# STM32H5F5 register map
File version: 1.0
CPU: CM33 r0p0, little endian, MPU, FPU, 4 interrupt priority bits
Registers are 32-bit, read-write, reset 0x0 unless marked. A register's access mark holds for its fields unless they carry their own. Offsets are from the block's base; [hi:lo] are bit positions; {n}, {i} and the like mark numbered series; 'fields as' and 'values as' point back to an identical list.

## RCC (part 2 of 2) — RCC register block
Base 0x44020C00
Same registers: RCC_S 0x54020C00
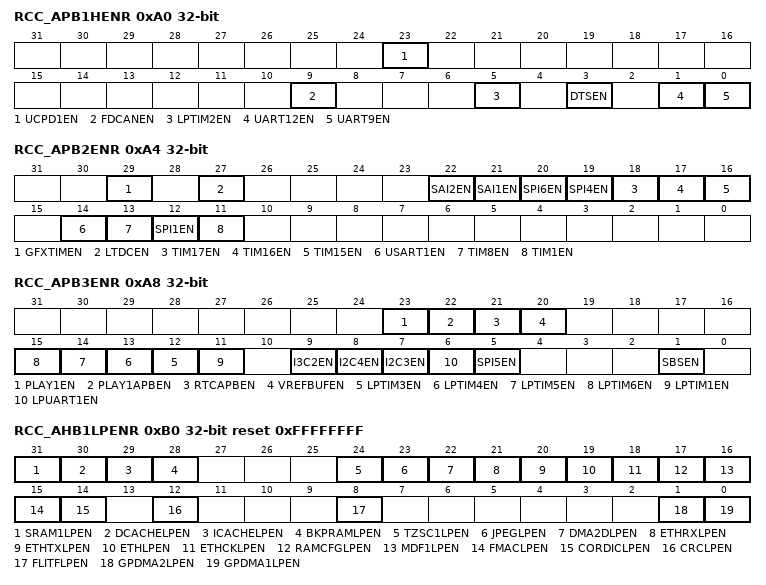
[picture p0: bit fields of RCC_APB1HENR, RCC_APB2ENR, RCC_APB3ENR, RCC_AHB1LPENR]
0xA0 RCC_APB1HENR — RCC APB1 peripheral clock register
  [23] UCPD1EN — UCPD1 clock enable
    0=UCPD1 clock disabled (default after reset); 1=UCPD1 clock enabled
  [9] FDCANEN — FDCAN1/2/3 clock enable
    0=FDCAN1/2/3 clock disabled (default after reset); 1=FDCAN1/2/3 clock enabled
  [5] LPTIM2EN — LPTIM2 clock enable
    0=LPTIM2 disabled (default after reset); 1=LPTIM2 peripheral clock enabled
  [3] DTSEN — DTS clock enable
    0=DTS clock disabled (default after reset); 1=DTS clock enabled
  [1] UART12EN — UART12 clock enable
    0=UART12 clock disabled (default after reset); 1=UART12 clock enabled
  [0] UART9EN — UART9 clock enable
    0=UART9 clock disabled (default after reset); 1=UART9 clock enabled
0xA4 RCC_APB2ENR — RCC APB2 peripheral clock register
  [29] GFXTIMEN — GFXTIM clock enable
    0=GFXTIM clock disabled (default after reset); 1=GFXTIM clock enabled
  [27] LTDCEN — LTDC clock enable
    0=LTDC clock disabled; 1=LTDC clock enabled
  [22] SAI2EN — SAI2 clock enable
    0=SAI2 clock disabled; 1=SAI2 clock enabled
  [21] SAI1EN — SAI1 clock enable
    0=SAI1 clock disabled (default after reset); 1=SAI1 clock enabled
  [20] SPI6EN — SPI6 clock enable
    0=SPI6 clock disabled (default after reset); 1=SPI6 clock enabled
  [19] SPI4EN — SPI4 clock enable
    0=SPI4 clock disabled (default after reset); 1=SPI4 clock enabled
  [18] TIM17EN — TIM17 clock enable
    0=TIM17 clock disabled (default after reset); 1=TIM17 clock enabled
  [17] TIM16EN — TIM16 clock enable
    0=TIM16 clock disabled (default after reset); 1=TIM16 clock enabled
  [16] TIM15EN — TIM15 clock enable
    0=TIM15 clock disabled (default after reset); 1=TIM15 clock enabled
  [14] USART1EN — USART1 clock enable
    0=USART1 clock disabled (default after reset); 1=USART1 clock enabled
  [13] TIM8EN — TIM8 clock enable
    0=TIM8 clock disabled (default after reset); 1=TIM8 clock enabled
  [12] SPI1EN — SPI1 clock enable
    0=SPI1 clock disabled (default after reset); 1=SPI1 clock enabled
  [11] TIM1EN — TIM1 clock enable
    0=TIM1 clock disabled (default after reset); 1=TIM1 clock enabled
0xA8 RCC_APB3ENR — RCC APB3 peripheral clock register
  [23] PLAY1EN — PLAY1 clock enable
    0=PLAY1 clock disabled (default after reset); 1=PLAY1 clock enabled
  [22] PLAY1APBEN — clock enable for PLAY1 configuration
    values as PLAY1EN
  [21] RTCAPBEN — RTC APB interface clock enable
    0=RTC APB interface clock disabled (default after reset); 1=RTC APB interface clock enabled
  [20] VREFBUFEN — VREFBUF clock enable
    0=VREFBUF clock disabled (default after reset); 1=VREFBUF clock enabled
  [n+9] LPTIM{n}EN (n=3..6) — LPTIM{n} clock enable
    0=LPTIM{n} clock disabled (default after reset); 1=LPTIM{n} clock enabled
  [11] LPTIM1EN — LPTIM1 clock enable
    0=LPTIM1 clock disabled (default after reset); 1=LPTIM1 clock enabled
  [9] I3C2EN — I3C2 clock enable
    0=I3C2 clock disabled (default after reset); 1=I3C2 clock enabled
  [8] I2C4EN — I2C4 clock enable
    0=I2C4 clock disabled (default after reset); 1=I2C4 clock enabled
  [7] I2C3EN — I2C3 clock enable
    0=I2C3 clock disabled (default after reset); 1=I2C3 clock enabled
  [6] LPUART1EN — LPUART1 clock enable
    0=LPUART1 clock disabled (default after reset); 1=LPUART1 clock enabled
  [5] SPI5EN — SPI5 clock enable
    0=SPI5 clock disabled (default after reset); 1=SPI5 clock enabled
  [1] SBSEN — SBS clock enable
    0=SBS clock disabled (default after reset); 1=SBS clock enabled
0xB0 RCC_AHB1LPENR reset 0xFFFFFFFF — RCC AHB1 sleep clock register
  [31] SRAM1LPEN — SRAM1 clock enable during Sleep mode
    0=SRAM1 clock disabled during Sleep mode; 1=SRAM1 clock enabled during Sleep mode (default after reset)
  [30] DCACHELPEN — DCACHE clock enable during Sleep mode
    0=DCACHE clock disabled during Sleep mode; 1=DCACHE clock enabled during Sleep mode (default after reset)
  [29] ICACHELPEN — ICACHE clock enable during Sleep mode
    0=ICACHE clock disabled during Sleep mode; 1=ICACHE clock enabled during Sleep mode (default after reset)
  [28] BKPRAMLPEN — BKPRAM clock enable during Sleep mode
    0=BKPRAM clock disabled during Sleep mode; 1=BKPRAM clock enabled during Sleep mode (default after reset)
  [24] TZSC1LPEN — TZSC1 clock enable during Sleep mode
    0=TZSC1 clock disabled during Sleep mode; 1=TZSC1 clock enabled during Sleep mode (default after reset)
  [23] JPEGLPEN — JPEG clock enable during Sleep mode
    0=JPEG clock disabled during Sleep mode; 1=JPEG clock enabled during Sleep mode (default after reset)
  [22] DMA2DLPEN — DMA2D clock enable during Sleep mode
    0=DMA2D clock disabled during Sleep mode; 1=DMA2D clock enabled during Sleep mode (default after reset)
  [21] ETHRXLPEN — ETHRX clock enable during Sleep mode
    0=ETHRX clock disabled during Sleep mode; 1=ETHRX clock enabled during Sleep mode (default after reset)
  [20] ETHTXLPEN — ETHTX clock enable during Sleep mode
    0=ETHTX clock disabled during Sleep mode; 1=ETHTX clock enabled during Sleep mode (default after reset)
  [19] ETHLPEN — ETH clock enable during Sleep mode
    0=ETH clock disabled during Sleep mode; 1=ETH clock enabled during Sleep mode (default after reset)
  [18] ETHCKLPEN — ETH internal clock enable during Sleep mode
    0=ETH internal clock disabled during Sleep mode; 1=ETH internal clock enabled during Sleep mode (default after reset)
  [17] RAMCFGLPEN — RAMCFG clock enable during Sleep mode
    0=RAMCFG clock disabled during Sleep mode; 1=RAMCFG clock enabled during Sleep mode (default after reset)
  [16] MDF1LPEN — MDF1 clock enable during Sleep mode
    0=MDF1 clock disabled during Sleep mode; 1=MDF1 clock enabled during Sleep mode (default after reset)
  [15] FMACLPEN — FMAC clock enable during Sleep mode
    0=FMAC clock disabled during Sleep mode; 1=FMAC clock enabled during Sleep mode (default after reset)
  [14] CORDICLPEN — CORDIC clock enable during Sleep mode
    0=CORDIC clock disabled during Sleep mode; 1=CORDIC clock enabled during Sleep mode (default after reset)
  [12] CRCLPEN — CRC clock enable during Sleep mode
    0=CRC clock disabled during Sleep mode; 1=CRC clock enabled during Sleep mode (default after reset)
  [8] FLITFLPEN — Flash interface (FLITF) clock enable during Sleep mode
    0=FLITF clock disabled during Sleep mode; 1=FLITF clock enabled during Sleep mode (default after reset)
  [1] GPDMA2LPEN — GPDMA2 clock enable during Sleep mode
    0=GPDMA2 clock disabled during Sleep mode; 1=GPDMA2 clock enabled during Sleep mode (default after reset)
  [0] GPDMA1LPEN — GPDMA1 clock enable during Sleep mode
    0=GPDMA1 clock disabled during Sleep mode; 1=GPDMA1 clock enabled during Sleep mode (default after reset)
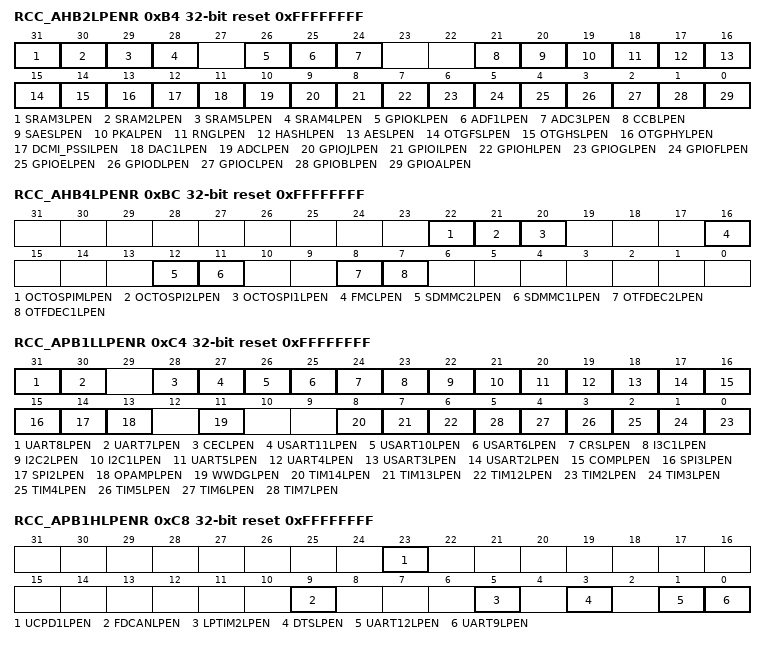
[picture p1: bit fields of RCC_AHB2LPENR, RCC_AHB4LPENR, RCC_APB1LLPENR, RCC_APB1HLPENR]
0xB4 RCC_AHB2LPENR reset 0xFFFFFFFF — RCC AHB2 sleep clock register
  [31] SRAM3LPEN — SRAM3 clock enable during Sleep mode
    0=SRAM3 clock disabled during Sleep mode; 1=SRAM3 clock enabled during Sleep mode (default after reset)
  [30] SRAM2LPEN — SRAM2 clock enable during Sleep mode
    0=SRAM2 clock disabled during Sleep mode; 1=SRAM2 clock enabled during Sleep mode (default after reset)
  [29] SRAM5LPEN — SRAM5 clock enable during Sleep mode
    0=SRAM5 clock disabled during Sleep mode; 1=SRAM5 clock enabled during Sleep mode (default after reset)
  [28] SRAM4LPEN — SRAM4 clock enable during Sleep mode
    0=SRAM4 clock disabled during Sleep mode; 1=SRAM4 clock enabled during Sleep mode (default after reset)
  [26] GPIOKLPEN — GPIOK clock enable during Sleep mode
    0=GPIOK clock disabled during Sleep mode; 1=GPIOK clock enabled during Sleep mode (default after reset)
  [25] ADF1LPEN — ADF1 clock enable during Sleep mode
    0=ADF1 clock disabled during Sleep mode; 1=ADF1 clock enabled during Sleep mode (default after reset)
  [24] ADC3LPEN — ADC3 clock enable during Sleep mode
    0=ADC3 clock disabled during Sleep mode; 1=ADC3 clock enabled during Sleep mode (default after reset)
  [21] CCBLPEN — CCB clock enable during Sleep mode
    0=CCB clock disabled during Sleep mode; 1=CCB clock enabled during Sleep mode (default after reset)
  [20] SAESLPEN — SAES clock enable during Sleep mode
    0=SAES clock disabled during Sleep mode; 1=SAES clock enabled during Sleep mode (default after reset)
  [19] PKALPEN — PKA clock enable during Sleep mode
    0=PKA clock disabled during Sleep mode; 1=PKA clock enabled during Sleep mode (default after reset)
  [18] RNGLPEN — RNG clock enable during Sleep mode
    0=RNG clock disabled during Sleep mode; 1=RNG clock enabled during Sleep mode (default after reset)
  [17] HASHLPEN — HASH clock enable during Sleep mode
    0=HASH clock disabled during Sleep mode; 1=HASH clock enabled during Sleep mode (default after reset)
  [16] AESLPEN — AES clock enable during Sleep mode
    0=AES clock disabled during Sleep mode; 1=AES clock enabled during Sleep mode (default after reset)
  [15] OTGFSLPEN — OTGFS clock enable during Sleep mode
    0=OTGFS clock disabled during Sleep mode; 1=OTGFS clock enabled during Sleep mode (default after reset)
  [14] OTGHSLPEN — OTGHS clock enable during Sleep mode
    0=OTGHS clock disabled during Sleep mode; 1=OTGHS clock enabled during Sleep mode (default after reset)
  [13] OTGPHYLPEN — OTGPHY clock enable during Sleep mode
    0=OTGPHY clock disabled during Sleep mode; 1=OTGPHY clock enabled during Sleep mode (default after reset)
  [12] DCMI_PSSILPEN — Digital camera interface clock enable during Sleep mode (DCMI or PSSI, depending which interface is active)
    0=DCMI/PSSI clock disabled during Sleep mode; 1=DCMI/PSSI clock enabled during Sleep mode (default after reset)
  [11] DAC1LPEN — DAC clock enable during Sleep mode
    0=DAC clock disabled during Sleep mode; 1=DAC clock enabled during Sleep mode (default after reset)
  [10] ADCLPEN — ADC1/2 clock enable during Sleep mode
    0=ADC1/2 clock disabled during Sleep mode; 1=ADC1/2 clock enabled during Sleep mode (default after reset)
  [9] GPIOJLPEN — GPIOJ clock enable during Sleep mode
    0=GPIOJ clock disabled during Sleep mode; 1=GPIOJ clock enabled during Sleep mode (default after reset)
  [8] GPIOILPEN — GPIOI clock enable during Sleep mode
    0=GPIOI clock disabled during Sleep mode; 1=GPIOI clock enabled during Sleep mode (default after reset)
  [7] GPIOHLPEN — GPIOH clock enable during Sleep mode
    0=GPIOH clock disabled during Sleep mode; 1=GPIOH clock enabled during Sleep mode (default after reset)
  [6] GPIOGLPEN — GPIOG clock enable during Sleep mode
    0=GPIOG clock disabled during Sleep mode; 1=GPIOG clock enabled during Sleep mode (default after reset)
  [5] GPIOFLPEN — GPIOF clock enable during Sleep mode
    0=GPIOF clock disabled during Sleep mode; 1=GPIOF clock enabled during Sleep mode (default after reset)
  [4] GPIOELPEN — GPIOE clock enable during Sleep mode
    0=GPIOE clock disabled during Sleep mode; 1=GPIOE clock enabled during Sleep mode (default after reset)
  [3] GPIODLPEN — GPIOD clock enable during Sleep mode
    0=GPIOD clock disabled during Sleep mode; 1=GPIOD clock enabled during Sleep mode (default after reset)
  [2] GPIOCLPEN — GPIOC clock enable during Sleep mode
    0=GPIOC clock disabled during Sleep mode; 1=GPIOC clock enabled during Sleep mode (default after reset)
  [1] GPIOBLPEN — GPIOB clock enable during Sleep mode
    0=GPIOB clock disabled during Sleep mode; 1=GPIOB clock enabled during Sleep mode (default after reset)
  [0] GPIOALPEN — GPIOA clock enable during Sleep mode
    0=GPIOA clock disabled during Sleep mode; 1=GPIOA clock enabled during Sleep mode (default after reset)
0xBC RCC_AHB4LPENR reset 0xFFFFFFFF — RCC AHB4 sleep clock register
  [22] OCTOSPIMLPEN — OCTOSPIM clock enable during Sleep mode
    0=OCTOSPIM clock disabled during Sleep mode; 1=OCTOSPIM clock enabled during Sleep mode (default after reset)
  [21] OCTOSPI2LPEN — OCTOSPI2 clock enable during Sleep mode
    0=OCTOSPI2 clock disabled during Sleep mode; 1=OCTOSPI2 clock enabled during Sleep mode (default after reset)
  [20] OCTOSPI1LPEN — OCTOSPI1 clock enable during Sleep mode
    0=OCTOSPI1 clock disabled during Sleep mode; 1=OCTOSPI1 clock enabled during Sleep mode (default after reset)
  [16] FMCLPEN — FMC clock enable during Sleep mode
    0=FMC clock disabled during Sleep mode; 1=FMC clock enabled during Sleep mode (default after reset)
  [12] SDMMC2LPEN — SDMMC2 and SDMMC2 delay clock enable during Sleep mode
    0=SDMMC2 and SDMMC2 delay clock disabled during Sleep mode; 1=SDMMC2 and SDMMC2 delay clock enabled during Sleep mode (default after reset)
  [11] SDMMC1LPEN — SDMMC1 and SDMMC1 delay clock enable during Sleep mode
    0=SDMMC1 and SDMMC1 delay clock disabled during Sleep mode; 1=SDMMC1 and SDMMC1 delay clock enabled during Sleep mode (default after reset)
  [8] OTFDEC2LPEN — OTFDEC2 clock enable during Sleep mode
    0=OTFDEC2 clock disabled during Sleep mode; 1=OTFDEC2 clock enabled during Sleep mode (default after reset)
  [7] OTFDEC1LPEN — OTFDEC1 clock enable during Sleep mode
    0=OTFDEC1 clock disabled during Sleep mode; 1=OTFDEC1 clock enabled during Sleep mode (default after reset)
0xC4 RCC_APB1LLPENR reset 0xFFFFFFFF — RCC APB1 sleep clock register
  [31] UART8LPEN — UART8 clock enable during Sleep mode
    0=UART8 clock disabled during Sleep mode; 1=UART8 clock enabled during Sleep mode (default after reset)
  [30] UART7LPEN — UART7 clock enable during Sleep mode
    0=UART7 clock disabled during Sleep mode; 1=UART7 clock enabled during Sleep mode (default after reset)
  [28] CECLPEN — HDMI-CEC clock enable during Sleep mode
    0=HDMI-CEC clock disabled during Sleep mode; 1=HDMI-CEC clock enabled during Sleep mode (default after reset)
  [27] USART11LPEN — USART11 clock enable during Sleep mode
    0=USART11 clock disabled during Sleep mode; 1=USART11 clock enabled during Sleep mode (default after reset)
  [26] USART10LPEN — USART10 clock enable during Sleep mode
    0=USART10 clock disabled during Sleep mode; 1=USART10 clock enabled during Sleep mode (default after reset)
  [25] USART6LPEN — USART6 clock enable during Sleep mode
    0=USART6 clock disabled during Sleep mode; 1=USART6 clock enabled during Sleep mode (default after reset)
  [24] CRSLPEN — CRS clock enable during Sleep mode
    0=CRS clock disabled during Sleep mode; 1=CRS clock enabled during Sleep mode (default after reset)
  [23] I3C1LPEN — I3C1 clock enable during Sleep mode
    0=I3C1 clock disabled during Sleep mode; 1=I3C1 clock enabled during Sleep mode (default after reset)
  [22] I2C2LPEN — I2C2 clock enable during Sleep mode
    0=I2C2 clock disabled during Sleep mode; 1=I2C2 clock enabled during Sleep mode (default after reset)
  [21] I2C1LPEN — I2C1 clock enable during Sleep mode
    0=I2C1 clock disabled during Sleep mode; 1=I2C1 clock enabled during Sleep mode (default after reset)
  [20] UART5LPEN — UART5 clock enable during Sleep mode
    0=UART5 clock disabled during Sleep mode; 1=UART5 clock enabled during Sleep mode (default after reset)
  [19] UART4LPEN — UART4 clock enable during Sleep mode
    0=UART4 clock disabled during Sleep mode; 1=UART4 clock enabled during Sleep mode (default after reset)
  [18] USART3LPEN — USART3 clock enable during Sleep mode
    0=USART3 clock disabled during Sleep mode; 1=USART3 clock enabled during Sleep mode (default after reset)
  [17] USART2LPEN — USART2 clock enable during Sleep mode
    0=USART2 clock disabled during Sleep mode; 1=USART2 clock enabled during Sleep mode (default after reset)
  [16] COMPLPEN — COMP clock enable during Sleep mode
    0=COMP clock disabled during Sleep mode; 1=COMP clock enabled during Sleep mode (default after reset)
  [15] SPI3LPEN — SPI3 clock enable during Sleep mode
    0=SPI3 clock disabled during Sleep mode; 1=SPI3 clock enabled during Sleep mode (default after reset)
  [14] SPI2LPEN — SPI2 clock enable during Sleep mode
    0=SPI2 clock disabled during Sleep mode; 1=SPI2 clock enabled during Sleep mode (default after reset)
  [13] OPAMPLPEN — OPAMP clock enable during Sleep mode
    0=OPAMP clock disabled during Sleep mode; 1=OPAMP clock enabled during Sleep mode (default after reset)
  [11] WWDGLPEN — WWDG clock enable during Sleep mode
    0=WWDG clock disabled during Sleep mode; 1=WWDG clock enabled during Sleep mode (default after reset)
  [8] TIM14LPEN — TIM14 clock enable during Sleep mode
    0=TIM14 clock disabled during Sleep mode; 1=TIM14 clock enabled during Sleep mode (default after reset)
  [7] TIM13LPEN — TIM13 clock enable during Sleep mode
    0=TIM13 clock disabled during Sleep mode; 1=TIM13 clock enabled during Sleep mode (default after reset)
  [6] TIM12LPEN — TIM12 clock enable during Sleep mode
    0=TIM12 clock disabled during Sleep mode; 1=TIM12 clock enabled during Sleep mode (default after reset)
  [n-2] TIM{n}LPEN (n=2..7) — TIM{n} clock enable during Sleep mode
    0=TIM{n} clock disabled during Sleep mode; 1=TIM{n} clock enabled during Sleep mode (default after reset)
0xC8 RCC_APB1HLPENR reset 0xFFFFFFFF — RCC APB1 sleep clock register
  [23] UCPD1LPEN — UCPD1 clock enable during Sleep mode
    0=UCPD1 clock disabled during Sleep mode; 1=UCPD1 clock enabled during Sleep mode (default after reset)
  [9] FDCANLPEN — FDCAN1/2/3 clock enable during Sleep mode
    0=FDCAN1/2/3 clock disabled during Sleep mode; 1=FDCAN1/2/3 clock enabled during Sleep mode (default after reset)
  [5] LPTIM2LPEN — LPTIM2 clock enable during Sleep mode
    0=LPTIM2 clock disabled during Sleep mode; 1=LPTIM2 clock enabled during Sleep mode (default after reset)
  [3] DTSLPEN — DTS clock enable during Sleep mode
    0=DTS clock disabled during Sleep mode; 1=DTS clock enabled during Sleep mode (default after reset)
  [1] UART12LPEN — UART12 clock enable during Sleep mode
    0=UART12 clock disabled during Sleep mode; 1=UART12 clock enabled during Sleep mode (default after reset)
  [0] UART9LPEN — UART9 clock enable during Sleep mode
    0=UART9 clock disabled during Sleep mode; 1=UART9 clock enabled during Sleep mode (default after reset)
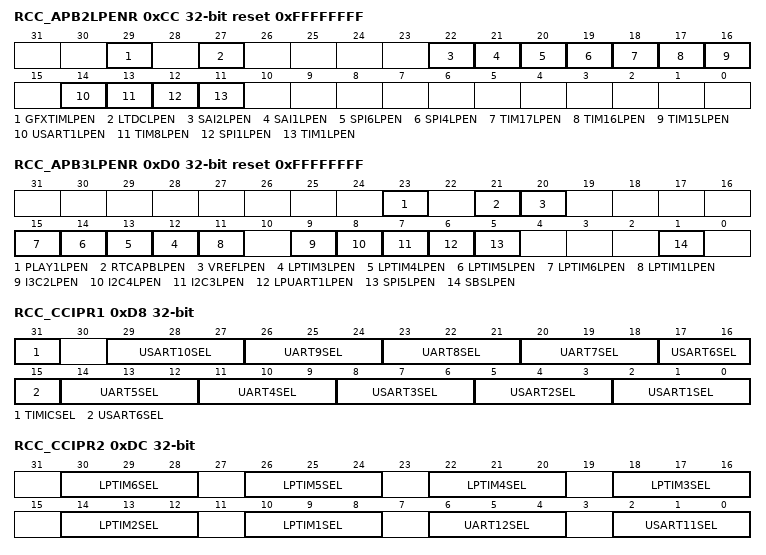
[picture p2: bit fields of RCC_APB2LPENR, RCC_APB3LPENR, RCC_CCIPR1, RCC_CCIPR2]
0xCC RCC_APB2LPENR reset 0xFFFFFFFF — RCC APB2 sleep clock register
  [29] GFXTIMLPEN — GFXTIM clock enable during Sleep mode
    0=GFXTIM clock disabled during Sleep mode; 1=GFXTIM clock enabled during Sleep mode (default after reset)
  [27] LTDCLPEN — LTDC clock enable during Sleep mode
    0=LTDC clock disabled during Sleep mode; 1=LTDC clock enabled during Sleep mode (default after reset)
  [22] SAI2LPEN — SAI2 clock enable during Sleep mode
    0=SAI2 clock disabled during Sleep mode; 1=SAI2 clock enabled during Sleep mode (default after reset)
  [21] SAI1LPEN — SAI1 clock enable during Sleep mode
    0=SAI1 clock disabled during Sleep mode; 1=SAI1 clock enabled during Sleep mode (default after reset)
  [20] SPI6LPEN — SPI6 clock enable during Sleep mode
    0=SPI6 clock disabled during Sleep mode; 1=SPI6 clock enabled during Sleep mode (default after reset)
  [19] SPI4LPEN — SPI4 clock enable during Sleep mode
    0=SPI4 clock disabled during Sleep mode; 1=SPI4 clock enabled during Sleep mode (default after reset)
  [18] TIM17LPEN — TIM17 clock enable during Sleep mode
    0=TIM17 clock disabled during Sleep mode; 1=TIM17 clock enabled during Sleep mode (default after reset)
  [17] TIM16LPEN — TIM16 clock enable during Sleep mode
    0=TIM16 clock disabled during Sleep mode; 1=TIM16 clock enabled during Sleep mode (default after reset)
  [16] TIM15LPEN — TIM15 clock enable during Sleep mode
    0=TIM15 clock disabled during Sleep mode; 1=TIM15 clock enabled during Sleep mode (default after reset)
  [14] USART1LPEN — USART1 clock enable during Sleep mode
    0=USART1 clock disabled during Sleep mode; 1=USART1 clock enabled during Sleep mode (default after reset)
  [13] TIM8LPEN — TIM8 clock enable during Sleep mode
    0=TIM8 clock disabled during Sleep mode; 1=TIM8 clock enabled during Sleep mode (default after reset)
  [12] SPI1LPEN — SPI1 clock enable during Sleep mode
    0=SPI1 clock disabled during Sleep mode; 1=SPI1 clock enabled during Sleep mode (default after reset)
  [11] TIM1LPEN — TIM1 clock enable during Sleep mode
    0=TIM1 clock disabled during Sleep mode; 1=TIM1 clock enabled during Sleep mode (default after reset)
0xD0 RCC_APB3LPENR reset 0xFFFFFFFF — RCC APB3 sleep clock register
  [23] PLAY1LPEN — PLAY1 clock enable during Sleep mode
    0=PLAY1 clock disabled during Sleep mode; 1=PLAY1 clock enabled during Sleep mode (default after reset)
  [21] RTCAPBLPEN — RTC APB interface clock enable during Sleep mode
    0=RTC APB interface clock disabled during Sleep mode; 1=RTC APB interface clock enabled during Sleep mode (default after reset)
  [20] VREFLPEN — VREFBUF clock enable during Sleep mode
    0=VREFBUF clock disabled during Sleep mode; 1=VREFBUF clock enabled during Sleep mode (default after reset)
  [n+9] LPTIM{n}LPEN (n=3..6) — LPTIM{n} clock enable during Sleep mode
    0=LPTIM{n} clock disabled during Sleep mode; 1=LPTIM{n} clock enabled during Sleep mode (default after reset)
  [11] LPTIM1LPEN — LPTIM1 clock enable during Sleep mode
    0=LPTIM1 clock disabled during Sleep mode; 1=LPTIM1 clock enabled during Sleep mode (default after reset)
  [9] I3C2LPEN — I3C2 clock enable during Sleep mode
    0=I3C2 clock disabled during Sleep mode; 1=I3C2 clock enabled during Sleep mode (default after reset)
  [8] I2C4LPEN — I2C4 clock enable during Sleep mode
    0=I2C4 clock disabled during Sleep mode; 1=I2C4 clock enabled during Sleep mode (default after reset)
  [7] I2C3LPEN — I2C3 clock enable during Sleep mode
    0=I2C3 clock disabled during Sleep mode; 1=I2C3 clock enabled during Sleep mode (default after reset)
  [6] LPUART1LPEN — LPUART1 clock enable during Sleep mode
    0=LPUART1 clock disabled during Sleep mode; 1=LPUART1 clock enabled during Sleep mode (default after reset)
  [5] SPI5LPEN — SPI5 clock enable during Sleep mode
    0=SPI5 clock disabled during Sleep mode; 1=SPI5 clock enabled during Sleep mode (default after reset)
  [1] SBSLPEN — SBS clock enable during Sleep mode
    0=SBS clock disabled during Sleep mode; 1=SBS clock enabled during Sleep mode (default after reset)
0xD8 RCC_CCIPR1 — RCC kernel clock configuration register
  [31] TIMICSEL — TIM12, TIM15, and LPTIM2 input capture source selection
    0=No internal clock available for timers input capture (default after reset); 1=hsi_ker_ck/1024, hsi_ker_ck/8, and csi_ker_ck/128 selected for timers input capture
  [29:27] USART10SEL — USART10 kernel clock source selection
    0=rcc_pclk1 selected as kernel clock (default after reset); 1=pll2_q_ck selected as kernel clock; 2=pll3_q_ck selected as kernel clock; 3=hsi_ker_ck selected as kernel clock; 4=csi_ker_ck selected as kernel clock; 5=lse_ck selected as kernel clock
  [26:24] UART9SEL — UART9 kernel clock source selection
    values as USART10SEL
  [23:21] UART8SEL — UART8 kernel clock source selection
    values as USART10SEL
  [20:18] UART7SEL — UART7 kernel clock source selection
    values as USART10SEL
  [17:15] USART6SEL — USART6 kernel clock source selection
    values as USART10SEL
  [14:12] UART5SEL — UART5 kernel clock source selection
    values as USART10SEL
  [11:9] UART4SEL — UART4 kernel clock source selection
    values as USART10SEL
  [8:6] USART3SEL — USART3 kernel clock source selection
    values as USART10SEL
  [5:3] USART2SEL — USART2 kernel clock source selection
    values as USART10SEL
  [2:0] USART1SEL — USART1 kernel clock source selection
    0=rcc_pclk2 selected as kernel clock (default after reset); 1=pll2_q_ck selected as kernel clock; 2=pll3_q_ck selected as kernel clock; 3=hsi_ker_ck selected as kernel clock; 4=csi_ker_ck selected as kernel clock; 5=lse_ck selected as kernel clock
0xDC RCC_CCIPR2 — RCC kernel clock configuration register
  [4n+6:4n+4] LPTIM{n}SEL (n=3..6) — LPTIM{n} kernel clock source selection
    0=rcc_pclk3 selected as kernel clock (default after reset); 1=pll2_p_ck selected as kernel clock; 2=pll3_r_ck selected as kernel clock; 3=lse_ker_ck selected as kernel clock; 4=lsi_ker_ck selected as kernel clock; 5=per_ck selected as kernel clock
  [14:12] LPTIM2SEL — LPTIM2 kernel clock source selection
    0=rcc_pclk1 selected as kernel clock (default after reset); 1=pll2_p_ck selected as kernel clock; 2=pll3_r_ck selected as kernel clock; 3=lse_ker_ck selected as kernel clock; 4=lsi_ker_ck selected as kernel clock; 5=per_ck selected as kernel clock
  [10:8] LPTIM1SEL — LPTIM1 kernel clock source selection
    values as LPTIM3SEL
  [6:4] UART12SEL — UART12 kernel clock source selection
    values as RCC_CCIPR1.USART10SEL
  [2:0] USART11SEL — USART11 kernel clock source selection
    values as RCC_CCIPR1.USART10SEL
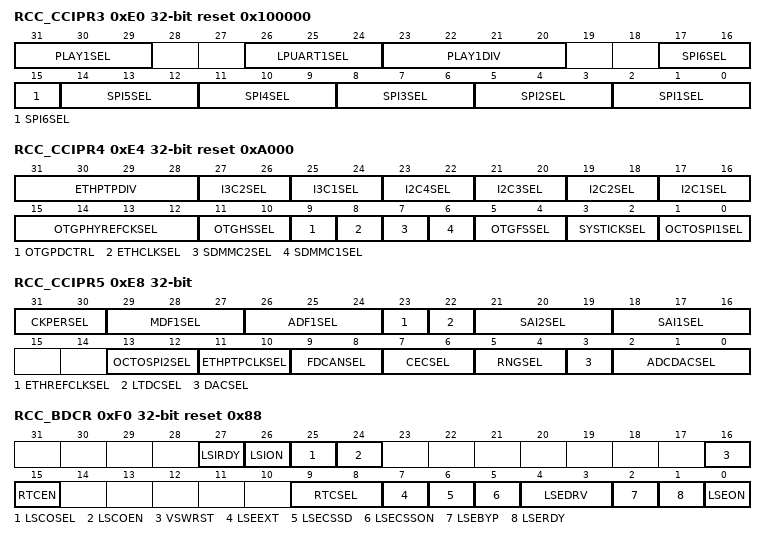
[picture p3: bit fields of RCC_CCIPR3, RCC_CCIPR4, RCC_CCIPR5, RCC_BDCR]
0xE0 RCC_CCIPR3 reset 0x100000 — RCC kernel clock configuration register
  [31:29] PLAY1SEL — PLAY1 kernel clock source selection
    0=rcc_pclk3 selected as kernel clock; 1=pll2_p_ck selected as kernel clock; 2=pll3_r_ck selected as kernel clock; 3=lse_ker_ck selected as kernel clock; 4=lsi_ker_ck selected as kernel clock; 5=per_ck selected as kernel clock
  [26:24] LPUART1SEL — LPUART1 kernel clock source selection
    0=rcc_pclk3 s elected as kernel clock (default after reset); 1=pll2_q_ck selected as kernel clock; 2=pll3_q_ck selected as kernel clock; 3=hsi_ker_ck selected as kernel clock; 4=csi_ker_ck selected as kernel clock; 5=lse_ck selected as kernel clock
  [23:20] PLAY1DIV — 2^N divider with N=0 to N=15
    0=N=0, PLAY1DIV_1; 1=N=1, PLAY1DIV_2; 2=N=2, PLAY1DIV_4; 3=N=3, PLAY1DIV_8; 15=N=15, PLAY1DIV_32768
  [17:15] SPI6SEL — SPI6 kernel clock source selection
    0=rcc_pclk2 selected as kernel clock (default after reset); 1=pll2_q_ck selected as kernel clock; 2=pll3_q_ck selected as kernel clock; 3=hsi_ker_ck selected as kernel clock; 4=csi_ker_ck selected as kernel clock; 5=hse_ck selected as kernel clock
  [14:12] SPI5SEL — SPI5 kernel clock source selection
    0=rcc_pclk3 selected as kernel clock (default after reset); 1=pll2_q_ck selected as kernel clock; 2=pll3_q_ck selected as kernel clock; 3=hsi_ker_ck selected as kernel clock; 4=csi_ker_ck selected as kernel clock; 5=hse_ck selected as kernel clock
  [11:9] SPI4SEL — SPI4 kernel clock source selection
    values as SPI6SEL
  [8:6] SPI3SEL — SPI3 kernel clock source selection
    0=pll1_q_ck selected as kernel clock (default after reset); 1=pll2_p_ck selected as kernel clock; 2=pll3_p_ck selected as kernel clock; 3=AUDIOCLK selected as kernel clock; 4=per_ck selected as kernel clock
  [5:3] SPI2SEL — SPI2 kernel clock source selection
    values as SPI3SEL
  [2:0] SPI1SEL — SPI1 kernel clock source selection
    values as SPI3SEL
0xE4 RCC_CCIPR4 reset 0xA000 — RCC kernel clock configuration register
  [31:28] ETHPTPDIV — Ethernet PTP clock division
    0=divided by 1 (default after reset); 1=divided by 2; 14=divided by 15; 15=divided by 16
  [27:26] I3C2SEL — I3C2 kernel clock source selection
    0=rcc_pclk3 selected as kernel clock (default after reset); 1=pll3_r_ck selected as kernel clock; 2=hsi_ker_ck selected as kernel clock; 3=csi_ker_ck selected as kernel clock
  [25:24] I3C1SEL — I3C1 kernel clock source selection
    0=rcc_pclk1 selected as kernel clock (default after reset); 1=pll3_r_ck selected as kernel clock; 2=hsi_ker_ck selected as kernel clock; 3=csi_ker_ck selected as kernel clock
  [23:22] I2C4SEL — I2C4 kernel clock source selection
    values as I3C2SEL
  [21:20] I2C3SEL — I2C3 kernel clock source selection
    values as I3C2SEL
  [19:18] I2C2SEL — I2C2 kernel clock source selection
    values as I3C1SEL
  [17:16] I2C1SEL — I2C1 kernel clock source selection
    values as I3C1SEL
  [15:12] OTGPHYREFCKSEL — OTG_HS PHY kernel clock frequency selection
    3=The kernel clock frequency is 16 MHz; 8=The kernel clock frequency is 19; 9=The kernel clock frequency is 20 MHz; 10=The kernel clock frequency is 24 MHz (default after reset); 14=The kernel clock frequency is 26 MHz; 11=The kernel clock frequency is 32 MHz
  [11:10] OTGHSSEL — OTG_HS PHY kernel clock source selection
    0=hse_ck selected as kernel clock (default after reset); 1=pll3_q_ck selected as kernel clock; 2=hse_ck / 2 selected as kernel clock; 3=pll1_q_ck / 2 selected as kernel clock
  [9] OTGPDCTRL — OTG_HS PHY common block power-down control
    0=In SUSPEND, PHY state machine, bias, and OTG_HS PHY PLL remain powered (default after reset); 1=In SUSPEND, PHY state machine, bias, and OTG_HS PHY PLL are powered down
  [8] ETHCLKSEL — ETH clock selection
    0=hse_ck (default after reset); 1=pll1_q_ck
  [7] SDMMC2SEL — SDMMC2 kernel clock source selection
    0=pll1_q_ck selected as kernel clock (default after reset); 1=pll2_r_ck selected as kernel clock
  [6] SDMMC1SEL — SDMMC1 kernel clock source selection
    values as SDMMC2SEL
  [5:4] OTGFSSEL — OTG_FS kernel clock source selection
    0=hsi48_ck selected as kernel clock (default after reset); 1=pll1_q_ck is selected as kernel clock; 2=pll3_q_ck selected as kernel clock; 3=clk48mohci selected as kernel clock
  [3:2] SYSTICKSEL — SYSTICK clock source selection
    0=rcc_hclk/8 selected as clock source (default after reset); 1=lsi_ker_ck selected as clock source; 2=lse_ck selected as clock source; 3=reserved, the kernel clock is disabled
  [1:0] OCTOSPI1SEL — OCTOSPI1 kernel clock source selection
    0=rcc_hclk4 selected as kernel clock (default after reset); 1=pll1_q_ck selected as kernel clock; 2=pll2_r_ck selected as kernel clock; 3=per_ck selected as kernel clock
0xE8 RCC_CCIPR5 — RCC kernel clock configuration register
  [31:30] CKPERSEL — per_ck clock source selection
    0=hsi_ker_ck selected as kernel clock (default after reset); 1=csi_ker_ck selected as kernel clock; 2=hse_ck selected as kernel clock; 3=reserved, the per_ck clock is disabled
  [29:27] MDF1SEL — MDF1 kernel clock source selection
    values as RCC_CCIPR3.SPI3SEL
  [26:24] ADF1SEL — ADF1 kernel clock source selection
    values as RCC_CCIPR3.SPI3SEL
  [23] ETHREFCLKSEL — ETH RMII reference kernel clock source selection
    0=ETH_RMII_REF_CLK (default after reset); 1=eth_clk_fb
  [22] LTDCSEL — LTDC kernel source selection
    0=pll3_r_ck selected as kernel clock (default after reset); 1=pll2_r_ck selected as kernel clock
  [21:19] SAI2SEL — SAI2 kernel clock source selection
    values as RCC_CCIPR3.SPI3SEL
  [18:16] SAI1SEL — SAI1 kernel clock source selection
    values as RCC_CCIPR3.SPI3SEL
  [13:12] OCTOSPI2SEL — OCTOSPI2 kernel clock source selection
    values as RCC_CCIPR4.OCTOSPI1SEL
  [11:10] ETHPTPCLKSEL — ETH PTP kernel clock source selection
    0=rcc_hclk1 selected as kernel clock (default after reset); 1=pll1_r_ck selected as kernel clock; 2=pll1_q_ck selected as kernel clock; 3=pll3_p_ckselected as kernel clock
  [9:8] FDCANSEL — FDCAN1, FDCAN2, and FDCAN3 kernel clock source selection
    0=hse_ck selected as kernel clock (default after reset); 1=pll1_q_ck selected as kernel clock; 2=pll2_q_ck selected as kernel clock; 3=reserved, the kernel clock is disabled
  [7:6] CECSEL — HDMI_CEC kernel clock source selection
    0=lse_ck selected as kernel clock (default after reset); 1=lsi_ker_ck selected as kernel clock; 2=csi_ker_ck/122 selected as kernel clock; 3=reserved, the kernel clock is disabled
  [5:4] RNGSEL — RNG kernel clock source selection
    0=hsi48_ck selected as kernel clock (default after reset); 1=pll1_q_ck selected as kernel clock; 2=lse_ck selected as kernel clock; 3=lsi_ker_ck selected as kernel clock
  [3] DACSEL — DAC sample and hold clock
    0=dac_hold_ck selected as kernel clock (default after reset); 1=dac_hold_ck selected as kernel clock
  [2:0] ADCDACSEL — ADC and DAC kernel clock source selection
    0=rcc_hclk selected as kernel clock (default after reset); 1=sys_ck selected as kernel clock; 2=pll2_r_ck selected as kernel clock; 3=hse_ck selected as kernel clock; 4=hsi_ker_ck selected as kernel clock; 5=csi_ker_ck selected as kernel clock
0xF0 RCC_BDCR reset 0x88 — RCC backup domain control register
  [27] LSIRDY ro — LSI oscillator ready
    0=LSI oscillator not ready; 1=LSI oscillator ready
  [26] LSION — LSI oscillator enable
    0=LSI oscillator off; 1=LSI oscillator on
  [25] LSCOSEL — Low-speed clock output selection
    0=LSI clock selected; 1=LSE clock selected
  [24] LSCOEN — Low-speed clock output (LSCO) enable
    0=LSCO output disabled; 1=LSCO output enabled
  [16] VSWRST — VSwitch domain software reset
    0=reset not activated (default after backup domain reset); 1=resets the entire VSW domain
  [15] RTCEN — RTC clock enable
    0=rtc_ck disabled (default after backup domain reset); 1=rtc_ck enabled
  [9:8] RTCSEL — RTC clock source selection
    0=no clock (default after backup domain reset); 1=LSE selected as RTC clock; 2=LSI selected as RTC clock; 3=HSE divided by RTCPRE value selected as RTC clock
  [7] LSEEXT — Low-speed external clock type in bypass mode
    1=LSE in digital mode (default after backup domain reset) (do not use if RTC is active)
  [6] LSECSSD ro — LSE clock security system failure detection
    0=no failure detected on 32 kHz oscillator (default after backup domain reset); 1=failure detected on 32 kHz oscillator
  [5] LSECSSON — LSE clock security system enable
    0=CSS on 32 kHz oscillator OFF (default after backup domain reset); 1=CSS on 32 kHz oscillator ON
  [4:3] LSEDRV — LSE oscillator driving capability
    1=medium-low drive; 2=medium-high drive; 3=highest drive
  [2] LSEBYP — LSE oscillator bypass
    0=LSE oscillator not bypassed (default after backup domain reset); 1=LSE oscillator bypassed
  [1] LSERDY — LSE oscillator ready
    0=LSE oscillator not ready (default after backup domain reset); 1=LSE oscillator ready
  [0] LSEON ro — LSE oscillator enabled
    0=LSE oscillator OFF (default after backup domain reset); 1=LSE oscillator ON
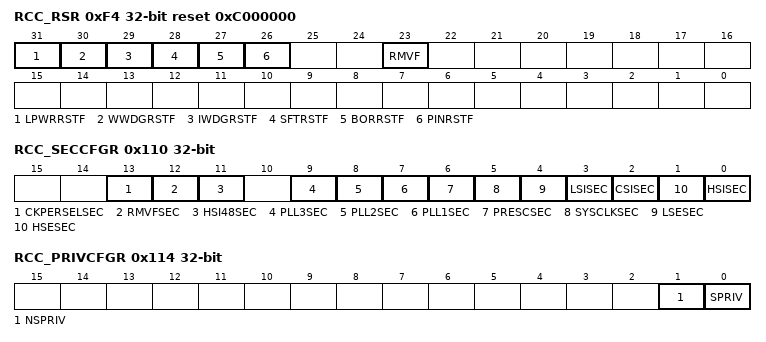
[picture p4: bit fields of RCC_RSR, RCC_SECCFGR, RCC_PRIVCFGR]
0xF4 RCC_RSR reset 0xC000000 — RCC reset status register
  [31] LPWRRSTF — Low-power reset flag
    0=no illegal low-power mode reset occurred; 1=illegal low-power mode reset occurred
  [30] WWDGRSTF — Window watchdog reset flag
    0=no window watchdog reset occurred from WWDG (default after power-on reset); 1=window watchdog reset occurred from WWDG
  [29] IWDGRSTF — Independent watchdog reset flag
    0=no independent watchdog reset occurred (default after power-on reset); 1=independent watchdog reset occurred
  [28] SFTRSTF — System reset from CPU reset flag
    0=no CPU software reset occurred (default after power-on reset); 1=a system reset has been generated by the CPU
  [27] BORRSTF — BOR reset flag
    0=no BOR reset occurred; 1=BOR reset occurred (default after power-on reset)
  [26] PINRSTF — Pin reset flag (NRST)
    0=no reset from pin occurred; 1=reset from pin occurred (default after power-on reset)
  [23] RMVF — Remove reset flag
    0=reset of the reset flags not activated (default after power-on reset); 1=resets the value of the reset flags
0x110 RCC_SECCFGR — RCC secure configuration register
  [all] fields
    0=non-secure; 1=secure
  [13] CKPERSELSEC — per_ck selection security
  [12] RMVFSEC — Remove reset flag security
  [11] HSI48SEC — HSI48 clock configuration and status bits security
  [9] PLL3SEC — PLL3 clock configuration and status bits security
  [8] PLL2SEC — PLL2 clock configuration and status bits security
  [7] PLL1SEC — PLL1 clock configuration and status bits security
  [6] PRESCSEC — AHBx/APBx prescaler configuration bits security
  [5] SYSCLKSEC — SYSCLK clock selection, STOPWUCK bit, clock output on MCO configuration security
  [4] LSESEC — LSE clock configuration and status bits security
  [3] LSISEC — LSI clock configuration and status bits security
  [2] CSISEC — CSI clock configuration and status bits security
  [1] HSESEC — HSE clock configuration bits, status bits and HSE_CSS security
  [0] HSISEC — HSI clock configuration and status bits security
0x114 RCC_PRIVCFGR — RCC privilege configuration register
  [1] NSPRIV — RCC non-secure functions privilege configuration
    0=Read and write to RCC non-secure functions can be done by privileged or unprivileged access; 1=Read and write to RCC non-secure functions can be done by privileged access only
  [0] SPRIV — RCC secure functions privilege configuration
    0=Read and write to RCC secure functions can be done by privileged or unprivileged access; 1=Read and write to RCC secure functions can be done by privileged access only
